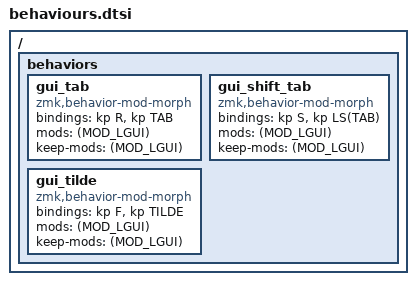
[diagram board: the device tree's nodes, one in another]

/ {
    behaviors {
        gui_tab: gui_tab {
            compatible = "zmk,behavior-mod-morph";
            #binding-cells = <0>;
            bindings = <&kp R>, <&kp TAB>;
            // which modifiers trigger morph
            mods = <(MOD_LGUI)>;
            // IMPORTANT: keep Cmd so host sees Cmd+Tab, not just Tab
            keep-mods = <(MOD_LGUI)>;
        };

        gui_shift_tab: gui_shift_tab {
            compatible = "zmk,behavior-mod-morph";
            #binding-cells = <0>;
            bindings = <&kp S>, <&kp LS(TAB)>;
            // which modifiers trigger morph
            mods = <(MOD_LGUI)>;
            // IMPORTANT: keep Cmd so host sees Cmd+Tab, not just Tab
            keep-mods = <(MOD_LGUI)>;
        };

            gui_tilde: gui_tilde {
            compatible = "zmk,behavior-mod-morph";
            #binding-cells = <0>;
            // tap alone  -> F
            // tap while Cmd held -> Tilde (with Cmd kept)
            bindings = <&kp F>, <&kp TILDE>;
            // which modifiers trigger morph
            mods = <(MOD_LGUI)>;
            // IMPORTANT: keep Cmd so host sees Cmd+Tab, not just Tab
            keep-mods = <(MOD_LGUI)>;
        };
    };
};
